AUTOSAR XML (schema 3.1.2)
package /Components/SWC_CoGBx
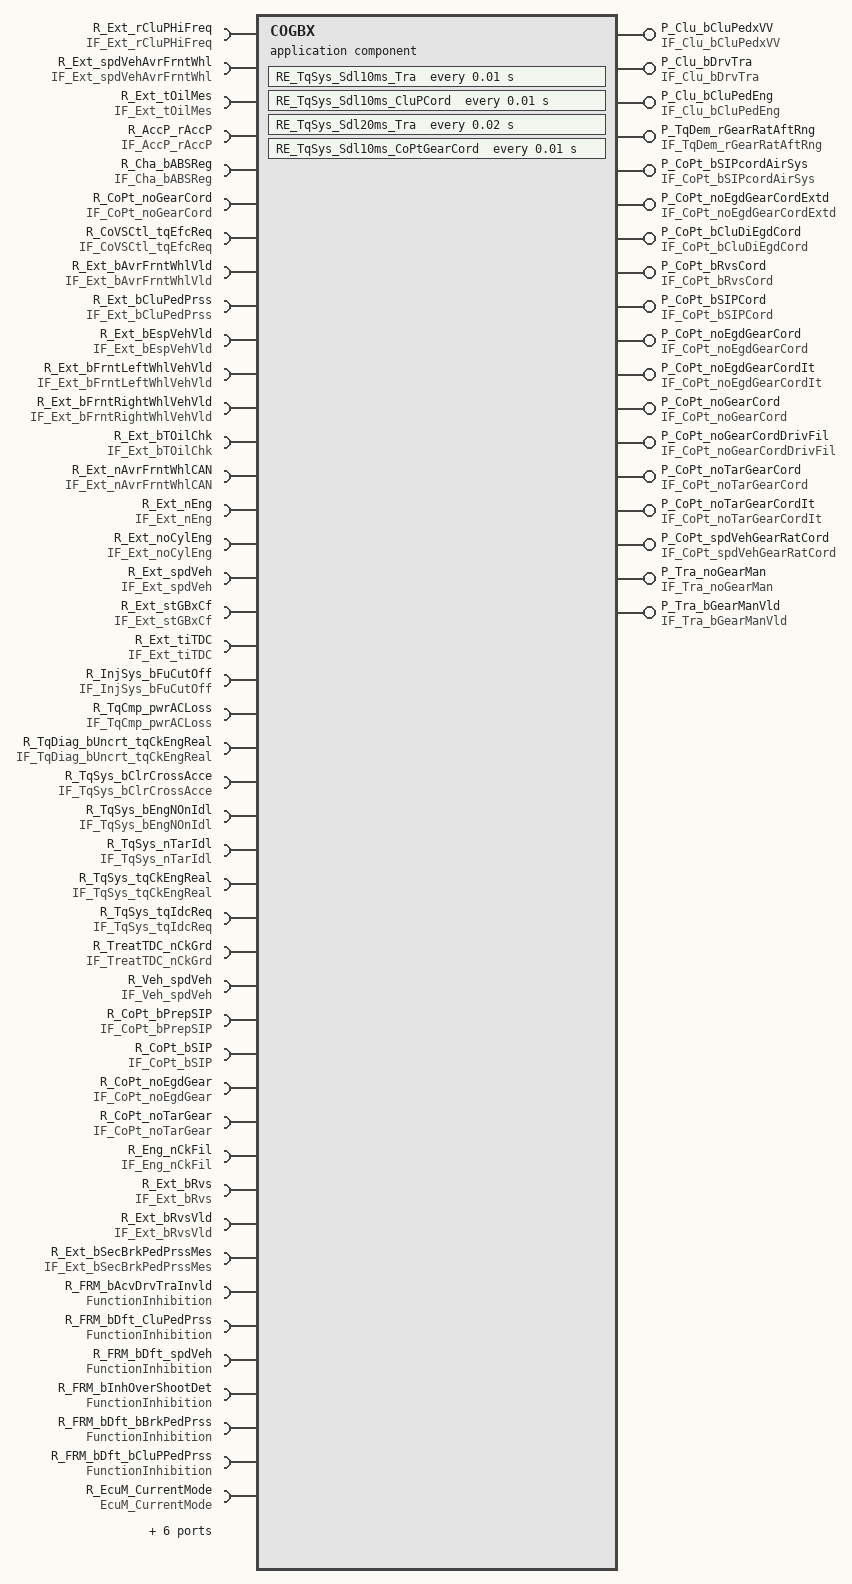
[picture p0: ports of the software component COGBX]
  application software component type COGBX
    43 x require port:
      R_Ext_rCluPHiFreq: unqueued-receiver-com-spec{data-element=Ext_rCluPHiFreq, init-value=ConstantValue, resync-time=0}, required-interface=IF_Ext_rCluPHiFreq
      R_Ext_spdVehAvrFrntWhl: unqueued-receiver-com-spec{data-element=Ext_spdVehAvrFrntWhl, init-value=Ext_spdVehAvrFrntWhl_in, resync-time=0}, required-interface=IF_Ext_spdVehAvrFrntWhl
      R_Ext_tOilMes: unqueued-receiver-com-spec{data-element=Ext_tOilMes, init-value=Ext_tOilMes_in, resync-time=0}, required-interface=IF_Ext_tOilMes
      R_AccP_rAccP: unqueued-receiver-com-spec{data-element=AccP_rAccP, init-value=ConstantValue1, resync-time=0}, required-interface=IF_AccP_rAccP
      R_Cha_bABSReg: unqueued-receiver-com-spec{data-element=Cha_bABSReg, init-value=Cha_bABSReg_in, resync-time=0}, required-interface=IF_Cha_bABSReg
      R_CoPt_noGearCord: unqueued-receiver-com-spec{data-element=CoPt_noGearCord, init-value=ConstantValue3, resync-time=0}, required-interface=IF_CoPt_noGearCord
      R_CoVSCtl_tqEfcReq: unqueued-receiver-com-spec{data-element=CoVSCtl_tqEfcReq, init-value=CoVSCtl_tqEfcReq_in, resync-time=0}, required-interface=IF_CoVSCtl_tqEfcReq
      R_Ext_bAvrFrntWhlVld: unqueued-receiver-com-spec{data-element=Ext_bAvrFrntWhlVld, init-value=Ext_bAvrFrntWhlVld_in, resync-time=0}, required-interface=IF_Ext_bAvrFrntWhlVld
      R_Ext_bCluPedPrss: unqueued-receiver-com-spec{data-element=Ext_bCluPedPrss, init-value=ConstantValue5, resync-time=0}, required-interface=IF_Ext_bCluPedPrss
      R_Ext_bEspVehVld: unqueued-receiver-com-spec{data-element=Ext_bEspVehVld, init-value=Ext_bEspVehVld_in, resync-time=0}, required-interface=IF_Ext_bEspVehVld
      R_Ext_bFrntLeftWhlVehVld: unqueued-receiver-com-spec{data-element=Ext_bFrntLeftWhlVehVld, init-value=Ext_bFrntLeftWhlVehVld_in, resync-time=0}, required-interface=IF_Ext_bFrntLeftWhlVehVld
      R_Ext_bFrntRightWhlVehVld: unqueued-receiver-com-spec{data-element=Ext_bFrntRightWhlVehVld, init-value=Ext_bFrntRightWhlVehVld_in, resync-time=0}, required-interface=IF_Ext_bFrntRightWhlVehVld
      R_Ext_bTOilChk: unqueued-receiver-com-spec{data-element=Ext_bTOilChk, init-value=Ext_bTOilChk_in, resync-time=0}, required-interface=IF_Ext_bTOilChk
      R_Ext_nAvrFrntWhlCAN: unqueued-receiver-com-spec{data-element=Ext_nAvrFrntWhlCAN, init-value=Ext_nAvrFrntWhlCAN_in, resync-time=0}, required-interface=IF_Ext_nAvrFrntWhlCAN
      R_Ext_nEng: unqueued-receiver-com-spec{data-element=Ext_nEng, init-value=ConstantValue7, resync-time=0}, required-interface=IF_Ext_nEng
      R_Ext_noCylEng: unqueued-receiver-com-spec{data-element=Ext_noCylEng, init-value=Ext_noCylEng_in, resync-time=0}, required-interface=IF_Ext_noCylEng
      R_Ext_spdVeh: unqueued-receiver-com-spec{data-element=Ext_spdVeh, init-value=ConstantValue9, resync-time=0}, required-interface=IF_Ext_spdVeh
      R_Ext_stGBxCf: unqueued-receiver-com-spec{data-element=Ext_stGBxCf, init-value=ConstantValue11, resync-time=0}, required-interface=IF_Ext_stGBxCf
      R_Ext_tiTDC: unqueued-receiver-com-spec{data-element=Ext_tiTDC, init-value=ConstantValue13, resync-time=0}, required-interface=IF_Ext_tiTDC
      R_InjSys_bFuCutOff: unqueued-receiver-com-spec{data-element=InjSys_bFuCutOff, init-value=InjSys_bFuCutOff_in, resync-time=0}, required-interface=IF_InjSys_bFuCutOff
      R_TqCmp_pwrACLoss: unqueued-receiver-com-spec{data-element=TqCmp_pwrACLoss, init-value=TqCmp_pwrACLoss_in, resync-time=0}, required-interface=IF_TqCmp_pwrACLoss
      R_TqDiag_bUncrt_tqCkEngReal: unqueued-receiver-com-spec{data-element=TqDiag_bUncrt_tqCkEngReal, init-value=TqDiag_bUncrt_tqCkEngReal_in, resync-time=0}, required-interface=IF_TqDiag_bUncrt_tqCkEngReal
      R_TqSys_bClrCrossAcce: unqueued-receiver-com-spec{data-element=TqSys_bClrCrossAcce, init-value=TqSys_bClrCrossAcce_in, resync-time=0}, required-interface=IF_TqSys_bClrCrossAcce
      R_TqSys_bEngNOnIdl: unqueued-receiver-com-spec{data-element=TqSys_bEngNOnIdl, init-value=ConstantValue15, resync-time=0}, required-interface=IF_TqSys_bEngNOnIdl
      R_TqSys_nTarIdl: unqueued-receiver-com-spec{data-element=TqSys_nTarIdl, init-value=ConstantValue17, resync-time=0}, required-interface=IF_TqSys_nTarIdl
      R_TqSys_tqCkEngReal: unqueued-receiver-com-spec{data-element=TqSys_tqCkEngReal, init-value=TqSys_tqCkEngReal_in, resync-time=0}, required-interface=IF_TqSys_tqCkEngReal
      R_TqSys_tqIdcReq: unqueued-receiver-com-spec{data-element=TqSys_tqIdcReq, init-value=ConstantValue19, resync-time=0}, required-interface=IF_TqSys_tqIdcReq
      R_TreatTDC_nCkGrd: unqueued-receiver-com-spec{data-element=TreatTDC_nCkGrd, init-value=ConstantValue21, resync-time=0}, required-interface=IF_TreatTDC_nCkGrd
      R_Veh_spdVeh: unqueued-receiver-com-spec{data-element=Veh_spdVeh, init-value=ConstantValue23, resync-time=0}, required-interface=IF_Veh_spdVeh
      R_CoPt_bPrepSIP: unqueued-receiver-com-spec{data-element=CoPt_bPrepSIP, init-value=CoPt_bPrepSIP_in, resync-time=0}, required-interface=IF_CoPt_bPrepSIP
      R_CoPt_bSIP: unqueued-receiver-com-spec{data-element=CoPt_bSIP, init-value=ConstantValue25, resync-time=0}, required-interface=IF_CoPt_bSIP
      R_CoPt_noEgdGear: unqueued-receiver-com-spec{data-element=CoPt_noEgdGear, init-value=CoPt_noEgdGear_in, resync-time=0}, required-interface=IF_CoPt_noEgdGear
      R_CoPt_noTarGear: unqueued-receiver-com-spec{data-element=CoPt_noTarGear, init-value=CoPt_noTarGear_in, resync-time=0}, required-interface=IF_CoPt_noTarGear
      R_Eng_nCkFil: unqueued-receiver-com-spec{data-element=Eng_nCkFil, init-value=ConstantValue27, resync-time=0}, required-interface=IF_Eng_nCkFil
      R_Ext_bRvs: unqueued-receiver-com-spec{data-element=Ext_bRvs, init-value=Ext_bRvs_in, resync-time=0}, required-interface=IF_Ext_bRvs
      R_Ext_bRvsVld: unqueued-receiver-com-spec{data-element=Ext_bRvsVld, init-value=Ext_bRvsVld_in, resync-time=0}, required-interface=IF_Ext_bRvsVld
      R_Ext_bSecBrkPedPrssMes: unqueued-receiver-com-spec{data-element=Ext_bSecBrkPedPrssMes, init-value=ConstantValue29, resync-time=0}, required-interface=IF_Ext_bSecBrkPedPrssMes
      R_FRM_bAcvDrvTraInvld: required-interface=FunctionInhibition
      R_FRM_bDft_CluPedPrss: required-interface=FunctionInhibition
      R_FRM_bDft_spdVeh: required-interface=FunctionInhibition
      R_FRM_bInhOverShootDet: required-interface=FunctionInhibition
      R_FRM_bDft_bBrkPedPrss: required-interface=FunctionInhibition
      R_FRM_bDft_bCluPPedPrss: required-interface=FunctionInhibition
    16 x provide port:
      P_Clu_bCluPedxVV: unqueued-sender-com-spec{data-element=Clu_bCluPedxVV, can-invalidate=false, init-value=Clu_bCluPedxVV_out}, provided-interface=IF_Clu_bCluPedxVV
      P_Clu_bDrvTra: unqueued-sender-com-spec{data-element=Clu_bDrvTra, can-invalidate=false, init-value=Clu_bDrvTra_out}, provided-interface=IF_Clu_bDrvTra
      P_Clu_bCluPedEng: unqueued-sender-com-spec{data-element=Clu_bCluPedEng, can-invalidate=false, init-value=Clu_bCluPedEng_out}, provided-interface=IF_Clu_bCluPedEng
      P_TqDem_rGearRatAftRng: unqueued-sender-com-spec{data-element=TqDem_rGearRatAftRng, can-invalidate=false, init-value=TqDem_rGearRatAftRng_out}, provided-interface=IF_TqDem_rGearRatAftRng
      P_CoPt_bSIPcordAirSys: unqueued-sender-com-spec{data-element=CoPt_bSIPcordAirSys, can-invalidate=false, init-value=CoPt_bSIPcordAirSys_out}, provided-interface=IF_CoPt_bSIPcordAirSys
      P_CoPt_noEgdGearCordExtd: unqueued-sender-com-spec{data-element=CoPt_noEgdGearCordExtd, can-invalidate=false, init-value=CoPt_noEgdGearCordExtd_out}, provided-interface=IF_CoPt_noEgdGearCordExtd
      P_CoPt_bCluDiEgdCord: unqueued-sender-com-spec{data-element=CoPt_bCluDiEgdCord, can-invalidate=false, init-value=ConstantValue31}, provided-interface=IF_CoPt_bCluDiEgdCord
      P_CoPt_bRvsCord: unqueued-sender-com-spec{data-element=CoPt_bRvsCord, can-invalidate=false, init-value=CoPt_bRvsCord_out}, provided-interface=IF_CoPt_bRvsCord
      P_CoPt_bSIPCord: unqueued-sender-com-spec{data-element=CoPt_bSIPCord, can-invalidate=false, init-value=ConstantValue33}, provided-interface=IF_CoPt_bSIPCord
      P_CoPt_noEgdGearCord: unqueued-sender-com-spec{data-element=CoPt_noEgdGearCord, can-invalidate=false, init-value=ConstantValue35}, provided-interface=IF_CoPt_noEgdGearCord
      P_CoPt_noEgdGearCordIt: unqueued-sender-com-spec{data-element=CoPt_noEgdGearCordIt, can-invalidate=false, init-value=ConstantValue37}, provided-interface=IF_CoPt_noEgdGearCordIt
      P_CoPt_noGearCord: unqueued-sender-com-spec{data-element=CoPt_noGearCord, can-invalidate=false, init-value=ConstantValue39}, provided-interface=IF_CoPt_noGearCord
      P_CoPt_noGearCordDrivFil: unqueued-sender-com-spec{data-element=CoPt_noGearCordDrivFil, can-invalidate=false, init-value=ConstantValue41}, provided-interface=IF_CoPt_noGearCordDrivFil
      P_CoPt_noTarGearCord: unqueued-sender-com-spec{data-element=CoPt_noTarGearCord, can-invalidate=false, init-value=CoPt_noTarGearCord_out}, provided-interface=IF_CoPt_noTarGearCord
      P_CoPt_noTarGearCordIt: unqueued-sender-com-spec{data-element=CoPt_noTarGearCordIt, can-invalidate=false, init-value=CoPt_noTarGearCordIt_out}, provided-interface=IF_CoPt_noTarGearCordIt
      P_CoPt_spdVehGearRatCord: unqueued-sender-com-spec{data-element=CoPt_spdVehGearRatCord, can-invalidate=false, init-value=CoPt_spdVehGearRatCord_out}, provided-interface=IF_CoPt_spdVehGearRatCord
    5 x require port:
      R_EcuM_CurrentMode: required-interface=EcuM_CurrentMode
      R_TqSys_EveSyncFrame30D_Tra: unqueued-receiver-com-spec{data-element=TqSys_EveSyncFrame30D_Tra, init-value=TqSys_EveSyncFrame30D_Tra_Cst, resync-time=0}, required-interface=IF_TqSys_EveSyncFrame30D_Tra
      R_TqSys_EveSyncFrame38D_Tra: unqueued-receiver-com-spec{data-element=TqSys_EveSyncFrame38D_Tra, init-value=TqSys_EveSyncFrame30D_Tra_cst, resync-time=0}, required-interface=IF_TqSys_EveSyncFrame38D_Tra
      R_TqSys_EveSync_Tra: unqueued-receiver-com-spec{data-element=TqSys_EveSync_Tra, init-value=TqSys_EveSync_Tra_Cst, resync-time=0}, required-interface=IF_TqSys_EveSync_Tra
      R_Tra_noGearMan: unqueued-receiver-com-spec{data-element=Tra_noGearMan, init-value=Tra_noGearMan, resync-time=0}, required-interface=IF_Tra_noGearMan
    provide port P_Tra_noGearMan: unqueued-sender-com-spec{data-element=Tra_noGearMan, can-invalidate=false, init-value=Tra_noGearMan}, provided-interface=IF_Tra_noGearMan
    require port R_UCE_stWkuMainRelSt: required-interface=IF_UCE_stWkuMainRelSt
    provide port P_Tra_bGearManVld: unqueued-sender-com-spec{data-element=Tra_bGearManVld, can-invalidate=false, init-value=Tra_bGearManVld_irv}, provided-interface=IF_Tra_bGearManVld
    require port R_Tra_bGearManVld: unqueued-receiver-com-spec{data-element=Tra_bGearManVld, init-value=Tra_bGearManVld_irv, resync-time=0}, required-interface=IF_Tra_bGearManVld
  66 x constant specification:
    Cha_bABSReg_in
      value:
        boolean literal Cha_bABSReg_in: type=DT_Cha_bABSReg, value=false
    Clu_bCluPedEng_out
      value:
        boolean literal Clu_bCluPedEng_out: type=DT_Clu_bCluPedEng, value=false
    Clu_bCluPedxVV_out
      value:
        boolean literal Clu_bCluPedxVV_out: type=DT_Clu_bCluPedxVV, value=false
    Clu_bDrvTra_out
      value:
        boolean literal Clu_bDrvTra_out: type=DT_Clu_bDrvTra, value=false
    ConstantValue
      value:
        integer literal ConstantValue: type=DT_Ext_rCluPHiFreq, value=0
    ConstantValue1
      value:
        integer literal ConstantValue1: type=DT_AccP_rAccP, value=0
    ConstantValue11
      value:
        integer literal ConstantValue11: type=DT_Ext_stGBxCf, value=0
    ConstantValue13
      value:
        integer literal ConstantValue13: type=DT_Ext_tiTDC, value=100
    ConstantValue15
      value:
        boolean literal ConstantValue15: type=DT_TqSys_bEngNOnIdl, value=true
    ConstantValue17
      value:
        integer literal ConstantValue17: type=DT_TqSys_nTarIdl, value=0
    ConstantValue19
      value:
        integer literal ConstantValue19: type=DT_TqSys_tqIdcReq, value=0
    ConstantValue21
      value:
        integer literal ConstantValue21: type=DT_TreatTDC_nCkGrd, value=0
    ConstantValue23
      value:
        integer literal ConstantValue23: type=DT_Veh_spdVeh, value=0
    ConstantValue25
      value:
        boolean literal ConstantValue25: type=DT_CoPt_bSIP, value=false
    ConstantValue27
      value:
        integer literal ConstantValue27: type=DT_Eng_nCkFil, value=0
    ConstantValue29
      value:
        boolean literal ConstantValue29: type=DT_Ext_bSecBrkPedPrssMes, value=false
    ConstantValue3
      value:
        integer literal ConstantValue3: type=DT_CoPt_noGearCord, value=0
    ConstantValue31
      value:
        boolean literal ConstantValue31: type=DT_CoPt_bCluDiEgdCord, value=false
    ConstantValue33
      value:
        boolean literal ConstantValue33: type=DT_CoPt_bSIPCord, value=false
    ConstantValue35
      value:
        integer literal ConstantValue35: type=DT_CoPt_noEgdGearCord, value=0
    ConstantValue37
      value:
        integer literal ConstantValue37: type=DT_CoPt_noEgdGearCordIt, value=0
    ConstantValue39
      value:
        integer literal ConstantValue39: type=DT_CoPt_noGearCord, value=0
    ConstantValue41
      value:
        integer literal ConstantValue41: type=DT_CoPt_noGearCordDrivFil, value=0
    ConstantValue5
      value:
        boolean literal ConstantValue5: type=DT_Ext_bCluPedPrss, value=false
    ConstantValue7
      value:
        integer literal ConstantValue7: type=DT_Ext_nEng, value=0
    ConstantValue9
      value:
        integer literal ConstantValue9: type=DT_Ext_spdVeh, value=0
    CoPt_bPrepSIP_in
      value:
        boolean literal CoPt_bPrepSIP_in: type=DT_CoPt_bPrepSIP, value=false
    CoPt_bRvsCord_out
      value:
        boolean literal CoPt_bRvsCord_out: type=DT_CoPt_bRvsCord, value=false
    CoPt_bSIPcordAirSys_out
      value:
        boolean literal CoPt_bSIPcordAirSys_out: type=DT_CoPt_bSIPcordAirSys, value=false
    CoPt_noEgdGear_in
      value:
        integer literal CoPt_noEgdGear_in: type=DT_CoPt_noEgdGear, value=0
    CoPt_noEgdGearCordExtd_out
      value:
        integer literal CoPt_noEgdGearCordExtd_out: type=DT_CoPt_noEgdGearCordExtd, value=0
    CoPt_noTarGear_in
      value:
        integer literal CoPt_noTarGear_in: type=DT_CoPt_noTarGear, value=0
    CoPt_noTarGearCord_out
      value:
        integer literal CoPt_noTarGearCord_out: type=DT_CoPt_noTarGearCord, value=0
    CoPt_noTarGearCordIt_out
      value:
        integer literal CoPt_noTarGearCordIt_out: type=DT_CoPt_noTarGearCordIt, value=0
    CoPt_spdVehGearRatCord_out
      value:
        integer literal CoPt_spdVehGearRatCord_out: type=DT_CoPt_spdVehGearRatCord, value=0
    CoVSCtl_tqEfcReq_in
      value:
        integer literal CoVSCtl_tqEfcReq_in: type=DT_CoVSCtl_tqEfcReq, value=0
    Ext_bAvrFrntWhlVld_in
      value:
        boolean literal Ext_bAvrFrntWhlVld_in: type=DT_Ext_bAvrFrntWhlVld, value=true
    Ext_bEspVehVld_in
      value:
        boolean literal Ext_bEspVehVld_in: type=DT_Ext_bEspVehVld, value=true
    Ext_bFrntLeftWhlVehVld_in
      value:
        boolean literal Ext_bFrntLeftWhlVehVld_in: type=DT_Ext_bFrntLeftWhlVehVld, value=true
    Ext_bFrntRightWhlVehVld_in
      value:
        boolean literal Ext_bFrntRightWhlVehVld_in: type=DT_Ext_bFrntRightWhlVehVld, value=true
    Ext_bRvs_in
      value:
        boolean literal Ext_bRvs_in: type=DT_Ext_bRvs, value=false
    Ext_bRvsVld_in
      value:
        boolean literal Ext_bRvsVld_in: type=DT_Ext_bRvsVld, value=false
    Ext_bTOilChk_in
      value:
        boolean literal Ext_bTOilChk_in: type=DT_Ext_bTOilChk, value=false
    Ext_nAvrFrntWhlCAN_in
      value:
        integer literal Ext_nAvrFrntWhlCAN_in: type=DT_Ext_nAvrFrntWhlCAN, value=0
    Ext_noCylEng_in
      value:
        integer literal Ext_noCylEng_in: type=DT_Ext_noCylEng, value=1
    Ext_spdVehAvrFrntWhl_in
      value:
        integer literal Ext_spdVehAvrFrntWhl_in: type=DT_Ext_spdVehAvrFrntWhl, value=0
    Ext_tOilMes_in
      value:
        integer literal Ext_tOilMes_in: type=DT_Ext_tOilMes, value=0
    InjSys_bFuCutOff_in
      value:
        boolean literal InjSys_bFuCutOff_in: type=DT_InjSys_bFuCutOff, value=false
    TqCmp_pwrACLoss_in
      value:
        integer literal TqCmp_pwrACLoss_in: type=DT_TqCmp_pwrACLoss, value=0
    TqDem_bGearRatCdnVld1_irv_Cst
      value:
        boolean literal TqDem_bGearRatCdnVld1_irv_Cst: type=DT_TqDem_bGearRatCdnVld1_irv, value=false
    TqDem_n6CylEngMvFil_irv
      value:
        integer literal TqDem_n6CylEngMvFil_irv: type=DT_TqDem_n6CylEngMvFil_irv, value=0
    TqDem_rGearRatAftRng_out
      value:
        integer literal TqDem_rGearRatAftRng_out: type=DT_TqDem_rGearRatAftRng, value=0
    TqDem_rPedPrssGrd_irv_Cst
      value:
        integer literal TqDem_rPedPrssGrd_irv_Cst: type=DT_TqDem_rPedPrssGrd_irv, value=0
    TqDem_spdVehFil1_irv
      value:
        integer literal TqDem_spdVehFil1_irv: type=DT_TqDem_spdVehFil1_irv, value=0
    TqDem_spdVehFil1_irv_Cst
      value:
        integer literal TqDem_spdVehFil1_irv_Cst: type=DT_TqDem_spdWhlFil1_irv, value=0
    TqDem_stGearratOverNRise_irv_Cst
      value:
        boolean literal TqDem_stGearratOverNRise_irv_Cst: type=DT_TqDem_stGearratOverNRise_irv, value=false
    TqDem_tqTqRealSyncFuseMv_irv_Cst
      value:
        integer literal TqDem_tqTqRealSyncFuseMv_irv_Cst: type=DT_TqDem_tqTqRealSyncFuseMv_irv, value=0
    TqDiag_bUncrt_tqCkEngReal_in
      value:
        boolean literal TqDiag_bUncrt_tqCkEngReal_in: type=DT_TqDiag_bUncrt_tqCkEngReal, value=false
    TqSys_bClrCrossAcce_in
      value:
        boolean literal TqSys_bClrCrossAcce_in: type=DT_TqSys_bClrCrossAcce, value=false
    TqSys_EveSync_Tra_Cst
      value:
        boolean literal TqSys_EveSync_Tra_Cst: type=DT_TqSys_EveSync_Tra, value=false
    TqSys_EveSyncFrame30D_Tra_cst
      value:
        boolean literal TqSys_EveSyncFrame30D_Tra_cst: type=DT_TqSys_EveSyncFrame38D_Tra, value=false
    TqSys_EveSyncFrame30D_Tra_Cst
      value:
        boolean literal TqSys_EveSyncFrame30D_Tra_Cst: type=DT_TqSys_EveSyncFrame30D_Tra, value=false
    TqSys_tqCkEngReal_in
      value:
        integer literal TqSys_tqCkEngReal_in: type=DT_TqSys_tqCkEngReal, value=0
    Tra_bGearManVld_irv
      value:
        boolean literal Tra_bGearManVld_irv: type=DT_Tra_bGearManVld, value=false
    Tra_noGearMan
      value:
        integer literal Tra_noGearMan: type=DT_Tra_noGearMan, value=0
    Tra_spdVehGearRatCord_irv_Cst
      value:
        integer literal Tra_spdVehGearRatCord_irv_Cst: type=DT_Tra_spdVehGearRatCord_irv, value=0
  internal behavior IB_CoGBx: component=COGBX
    timing event EV_TqSys_Sdl10ms_Tra: start-on-event=RE_TqSys_Sdl10ms_Tra, period=0.01
    timing event EV_TqSys_Sdl10ms_CluPCord: start-on-event=RE_TqSys_Sdl10ms_CluPCord, period=0.01
    data received event EV_TqSys_EveSyncFrame38D_Tra: start-on-event=RE_TqSys_EveSyncFrame38D_Tra, data=R_TqSys_EveSyncFrame38D_Tra.TqSys_EveSyncFrame38D_Tra
    mode switch event EV_CoGBx_001_MSE: start-on-event=RE_CoGBx_001_MSE, activation=ENTRY, mode=R_EcuM_CurrentMode.currentMode.RUN
    data received event EV_TqSys_EveSync_Tra: start-on-event=RE_TqSys_EveSync_Tra, data=R_TqSys_EveSync_Tra.TqSys_EveSync_Tra
    timing event EV_TqSys_Sdl20ms_Tra: start-on-event=RE_TqSys_Sdl20ms_Tra, period=0.02
    timing event EV_TqSys_Sdl10ms_CoPtGearCord: start-on-event=RE_TqSys_Sdl10ms_CoPtGearCord, period=0.01
    data received event EV_TqSys_EveSyncFrame30D_Tra: start-on-event=RE_TqSys_EveSyncFrame30D_Tra, data=R_TqSys_EveSyncFrame30D_Tra.TqSys_EveSyncFrame30D_Tra
    8 x inter runnable variable, all with sw-calibration-access=READ-WRITE, communication-approach=EXPLICIT:
      TqDem_spdVehFil1_irv: type=DT_TqDem_spdVehFil1_irv, init-value=TqDem_spdVehFil1_irv
      TqDem_stGearratOverNRise_irv: type=DT_TqDem_stGearratOverNRise_irv, init-value=TqDem_stGearratOverNRise_irv_Cst
      TqDem_n6CylEngMvFil_irv: type=DT_TqDem_n6CylEngMvFil_irv, init-value=TqDem_n6CylEngMvFil_irv
      TqDem_spdWhlFil1_irv: type=DT_TqDem_spdWhlFil1_irv, init-value=TqDem_spdVehFil1_irv_Cst
      TqDem_tqTqRealSyncFuseMv_irv: type=DT_TqDem_tqTqRealSyncFuseMv_irv, init-value=TqDem_tqTqRealSyncFuseMv_irv_Cst
      TqDem_bGearRatCdnVld1_irv: type=DT_TqDem_bGearRatCdnVld1_irv, init-value=TqDem_bGearRatCdnVld1_irv_Cst
      Tra_spdVehGearRatCord_irv: type=DT_Tra_spdVehGearRatCord_irv, init-value=Tra_spdVehGearRatCord_irv_Cst
      TqDem_rPedPrssGrd_irv: type=DT_TqDem_rPedPrssGrd_irv, init-value=TqDem_rPedPrssGrd_irv_Cst
    8 x runnable:
      RE_TqSys_EveSyncFrame38D_Tra: written-variable=TqDem_spdVehFil1_irv
        data receive point dr_Ext_spdVeh: data-element=R_Ext_spdVeh.Ext_spdVeh
      RE_CoGBx_001_MSE: written-variable=[TqDem_stGearratOverNRise_irv, TqDem_bGearRatCdnVld1_irv, TqDem_rPedPrssGrd_irv, TqDem_n6CylEngMvFil_irv, TqDem_spdVehFil1_irv, TqDem_spdWhlFil1_irv, Tra_spdVehGearRatCord_irv, TqDem_tqTqRealSyncFuseMv_irv]
        18 x data send point:
          DS_CoPt_bRvsCord: data-element=P_CoPt_bRvsCord.CoPt_bRvsCord
          DS_CoPt_spdVehGearRatCord: data-element=P_CoPt_spdVehGearRatCord.CoPt_spdVehGearRatCord
          ds_CoPt_bSIPCord: data-element=P_CoPt_bSIPCord.CoPt_bSIPCord
          DS_Tra_noGearMan: data-element=P_Tra_noGearMan.Tra_noGearMan
          ds_CoPt_noEgdGearCord: data-element=P_CoPt_noEgdGearCord.CoPt_noEgdGearCord
          ds_CoPt_noGearCordDrivFil: data-element=P_CoPt_noGearCordDrivFil.CoPt_noGearCordDrivFil
          DS_Tra_bGearManVld: data-element=P_Tra_bGearManVld.Tra_bGearManVld
          DS_Clu_bCluPedEng: data-element=P_Clu_bCluPedEng.Clu_bCluPedEng
          DS_Clu_bCluPedxVV: data-element=P_Clu_bCluPedxVV.Clu_bCluPedxVV
          DS_CoPt_noTarGearCord: data-element=P_CoPt_noTarGearCord.CoPt_noTarGearCord
          ds_CoPt_bCluDiEgdCord: data-element=P_CoPt_bCluDiEgdCord.CoPt_bCluDiEgdCord
          DS_CoPt_bSIPcordAirSys: data-element=P_CoPt_bSIPcordAirSys.CoPt_bSIPcordAirSys
          DS_Clu_bDrvTra: data-element=P_Clu_bDrvTra.Clu_bDrvTra
          ds_CoPt_noGearCord: data-element=P_CoPt_noGearCord.CoPt_noGearCord
          DS_TqDem_rGearRatAftRng: data-element=P_TqDem_rGearRatAftRng.TqDem_rGearRatAftRng
          DS_CoPt_noTarGearCordIt: data-element=P_CoPt_noTarGearCordIt.CoPt_noTarGearCordIt
          ds_CoPt_noEgdGearCordIt: data-element=P_CoPt_noEgdGearCordIt.CoPt_noEgdGearCordIt
          DS_CoPt_noEgdGearCordExtd: data-element=P_CoPt_noEgdGearCordExtd.CoPt_noEgdGearCordExtd
      RE_TqSys_Sdl10ms_CoPtGearCord: read-variable=Tra_spdVehGearRatCord_irv
        14 x data receive point:
          DR_CoPt_noTarGear: data-element=R_CoPt_noTarGear.CoPt_noTarGear
          dr_Ext_stGBxCf: data-element=R_Ext_stGBxCf.Ext_stGBxCf
          DR_Ext_bRvsVld: data-element=R_Ext_bRvsVld.Ext_bRvsVld
          dr_Ext_bSecBrkPedPrssMes: data-element=R_Ext_bSecBrkPedPrssMes.Ext_bSecBrkPedPrssMes
          DR_Tra_noGearMan: data-element=R_Tra_noGearMan.Tra_noGearMan
          dr_Eng_nCkFil: data-element=R_Eng_nCkFil.Eng_nCkFil
          DR_CoPt_noEgdGear: data-element=R_CoPt_noEgdGear.CoPt_noEgdGear
          dr_Ext_bCluPedPrss: data-element=R_Ext_bCluPedPrss.Ext_bCluPedPrss
          dr_Veh_spdVeh: data-element=R_Veh_spdVeh.Veh_spdVeh
          DR_CoPt_bPrepSIP: data-element=R_CoPt_bPrepSIP.CoPt_bPrepSIP
          DR_Ext_bRvs: data-element=R_Ext_bRvs.Ext_bRvs
          DR_Tra_bGearManVld: data-element=R_Tra_bGearManVld.Tra_bGearManVld
          dr_CoPt_bSIP: data-element=R_CoPt_bSIP.CoPt_bSIP
          dr_AccP_rAccP: data-element=R_AccP_rAccP.AccP_rAccP
        12 x data send point:
          ds_CoPt_bSIPCord: data-element=P_CoPt_bSIPCord.CoPt_bSIPCord
          ds_CoPt_noEgdGearCord: data-element=P_CoPt_noEgdGearCord.CoPt_noEgdGearCord
          DS_CoPt_bSIPcordAirSys: data-element=P_CoPt_bSIPcordAirSys.CoPt_bSIPcordAirSys
          DS_CoPt_bRvsCord: data-element=P_CoPt_bRvsCord.CoPt_bRvsCord
          ds_CoPt_bCluDiEgdCord: data-element=P_CoPt_bCluDiEgdCord.CoPt_bCluDiEgdCord
          DS_CoPt_noEgdGearCordExtd: data-element=P_CoPt_noEgdGearCordExtd.CoPt_noEgdGearCordExtd
          DS_CoPt_noTarGearCord: data-element=P_CoPt_noTarGearCord.CoPt_noTarGearCord
          ds_CoPt_noGearCord: data-element=P_CoPt_noGearCord.CoPt_noGearCord
          ds_CoPt_noGearCordDrivFil: data-element=P_CoPt_noGearCordDrivFil.CoPt_noGearCordDrivFil
          DS_CoPt_noTarGearCordIt: data-element=P_CoPt_noTarGearCordIt.CoPt_noTarGearCordIt
          DS_CoPt_spdVehGearRatCord: data-element=P_CoPt_spdVehGearRatCord.CoPt_spdVehGearRatCord
          ds_CoPt_noEgdGearCordIt: data-element=P_CoPt_noEgdGearCordIt.CoPt_noEgdGearCordIt
        sync call SC_FRM_bDft_bBrkPedPrss: operation=R_FRM_bDft_bBrkPedPrss.GetFunctionPermission
        sync call SC_FRM_bDft_bCluPPedPrss: operation=R_FRM_bDft_bCluPPedPrss.GetFunctionPermission
        sync call SC_FRM_bDft_spdVeh: operation=R_FRM_bDft_spdVeh.GetFunctionPermission
      RE_TqSys_Sdl10ms_CluPCord
        data receive point dr_Ext_rCluPHiFreq: data-element=R_Ext_rCluPHiFreq.Ext_rCluPHiFreq
        data send point DS_Clu_bCluPedEng: data-element=P_Clu_bCluPedEng.Clu_bCluPedEng
        data send point DS_Clu_bCluPedxVV: data-element=P_Clu_bCluPedxVV.Clu_bCluPedxVV
        data send point DS_Clu_bDrvTra: data-element=P_Clu_bDrvTra.Clu_bDrvTra
        sync call SC_FRM_bAcvDrvTraInvld: operation=R_FRM_bAcvDrvTraInvld.GetFunctionPermission
      RE_TqSys_EveSyncFrame30D_Tra: written-variable=TqDem_spdWhlFil1_irv
        data receive point DR_Ext_spdVehAvrFrntWhl: data-element=R_Ext_spdVehAvrFrntWhl.Ext_spdVehAvrFrntWhl
      RE_TqSys_EveSync_Tra: read-variable=[TqDem_rPedPrssGrd_irv, TqDem_bGearRatCdnVld1_irv], written-variable=[TqDem_tqTqRealSyncFuseMv_irv, TqDem_n6CylEngMvFil_irv, TqDem_stGearratOverNRise_irv]
        14 x data receive point:
          DR_Ext_noCylEng: data-element=R_Ext_noCylEng.Ext_noCylEng
          dr_Ext_nEng: data-element=R_Ext_nEng.Ext_nEng
          dr_TreatTDC_nCkGrd: data-element=R_TreatTDC_nCkGrd.TreatTDC_nCkGrd
          dr_TqSys_bEngNOnIdl: data-element=R_TqSys_bEngNOnIdl.TqSys_bEngNOnIdl
          dr_Ext_bCluPedPrss: data-element=R_Ext_bCluPedPrss.Ext_bCluPedPrss
          DR_InjSys_bFuCutOff: data-element=R_InjSys_bFuCutOff.InjSys_bFuCutOff
          dr_Ext_tiTDC: data-element=R_Ext_tiTDC.Ext_tiTDC
          DR_Ext_tOilMes: data-element=R_Ext_tOilMes.Ext_tOilMes
          DR_Tra_noGearMan: data-element=R_Tra_noGearMan.Tra_noGearMan
          DR_TqCmp_pwrACLoss: data-element=R_TqCmp_pwrACLoss.TqCmp_pwrACLoss
          dr_TqSys_tqIdcReq: data-element=R_TqSys_tqIdcReq.TqSys_tqIdcReq
          DR_Ext_bTOilChk: data-element=R_Ext_bTOilChk.Ext_bTOilChk
          DR_TqSys_tqCkEngReal: data-element=R_TqSys_tqCkEngReal.TqSys_tqCkEngReal
          DR_TqDiag_bUncrt_tqCkEngReal: data-element=R_TqDiag_bUncrt_tqCkEngReal.TqDiag_bUncrt_tqCkEngReal
        sync call SC_FRM_bInhOverShootDet: operation=R_FRM_bInhOverShootDet.GetFunctionPermission
      RE_TqSys_Sdl20ms_Tra
        4 x data receive point:
          DR_Ext_bAvrFrntWhlVld: data-element=R_Ext_bAvrFrntWhlVld.Ext_bAvrFrntWhlVld
          DR_Ext_bFrntLeftWhlVehVld: data-element=R_Ext_bFrntLeftWhlVehVld.Ext_bFrntLeftWhlVehVld
          DR_Ext_bFrntRightWhlVehVld: data-element=R_Ext_bFrntRightWhlVehVld.Ext_bFrntRightWhlVehVld
          DR_Ext_bEspVehVld: data-element=R_Ext_bEspVehVld.Ext_bEspVehVld
        data send point DS_Tra_bGearManVld: data-element=P_Tra_bGearManVld.Tra_bGearManVld
        sync call SC_FRM_bDft_spdVeh: operation=R_FRM_bDft_spdVeh.GetFunctionPermission
      RE_TqSys_Sdl10ms_Tra: read-variable=[TqDem_tqTqRealSyncFuseMv_irv, TqDem_spdVehFil1_irv, TqDem_stGearratOverNRise_irv, TqDem_spdWhlFil1_irv, TqDem_n6CylEngMvFil_irv], written-variable=[Tra_spdVehGearRatCord_irv, TqDem_rPedPrssGrd_irv, TqDem_bGearRatCdnVld1_irv]
        10 x data receive point:
          DR_CoVSCtl_tqEfcReq: data-element=R_CoVSCtl_tqEfcReq.CoVSCtl_tqEfcReq
          dr_Ext_nEng: data-element=R_Ext_nEng.Ext_nEng
          dr_Ext_spdVeh: data-element=R_Ext_spdVeh.Ext_spdVeh
          dr_AccP_rAccP: data-element=R_AccP_rAccP.AccP_rAccP
          DR_Cha_bABSReg: data-element=R_Cha_bABSReg.Cha_bABSReg
          DR_TqSys_bClrCrossAcce: data-element=R_TqSys_bClrCrossAcce.TqSys_bClrCrossAcce
          dr_TqSys_nTarIdl: data-element=R_TqSys_nTarIdl.TqSys_nTarIdl
          dr_CoPt_noGearCord: data-element=R_CoPt_noGearCord.CoPt_noGearCord
          DR_Ext_nAvrFrntWhlCAN: data-element=R_Ext_nAvrFrntWhlCAN.Ext_nAvrFrntWhlCAN
          DR_Ext_noCylEng: data-element=R_Ext_noCylEng.Ext_noCylEng
        data send point DS_Tra_noGearMan: data-element=P_Tra_noGearMan.Tra_noGearMan
        data send point DS_TqDem_rGearRatAftRng: data-element=P_TqDem_rGearRatAftRng.TqDem_rGearRatAftRng
        sync call SC_FRM_bDft_CluPedPrss: operation=R_FRM_bDft_CluPedPrss.GetFunctionPermission
        sync call SC_FRM_bDft_bBrkPedPrss: operation=R_FRM_bDft_bBrkPedPrss.GetFunctionPermission
  swc implementation Imp_CoGBx: programming-language=C, behavior=IB_CoGBx
    code-descriptors:
      code CodeDescriptor: type=SRC
        37 x xfile:
          CoGBx2096_fct_c: url=CoGBx2096_fct.c
          TqSys_Sdl10ms_Tra_1_fct_c: url=TqSys_Sdl10ms_Tra_1_fct.c
          TqSys_Sdl10ms_CluPCord_fct_h: url=TqSys_Sdl10ms_CluPCord_fct.h
          TqSys_EveSync_Tra_2_fct_h: url=TqSys_EveSync_Tra_2_fct.h
          CoGBx_h: url=CoGBx.h
          CoGBx_2096_lut_c: url=CoGBx_2096_lut.c
          TqSys_EveSync_Tra_2_fct_c: url=TqSys_EveSync_Tra_2_fct.c
          TqSys_EveSync_Tra_1_fct_c: url=TqSys_EveSync_Tra_1_fct.c
          TqSys_Sdl10ms_Tra_2_fct_h: url=TqSys_Sdl10ms_Tra_2_fct.h
          TqSys_EveSync_Tra_1_fct_h: url=TqSys_EveSync_Tra_1_fct.h
          CoGbx_2040_calibrations_h: url=CoGbx_2040_calibrations.h
          TqSys_Sdl10ms_CoPtGearCord_fct_c: url=TqSys_Sdl10ms_CoPtGearCord_fct.c
          CoGBx_2096_lut_h: url=CoGBx_2096_lut.h
          CoGbx_2040_calibrations_c: url=CoGbx_2040_calibrations.c
          CoGBx_2096_calibrations_c: url=CoGBx_2096_calibrations.c
          TqSys_EveSyncFrame38D_Tra_fct_h: url=TqSys_EveSyncFrame38D_Tra_fct.h
          CoGBx_MemMap_h: url=CoGBx_MemMap.h
          TqSys_Sdl20ms_Tra_fct_c: url=TqSys_Sdl20ms_Tra_fct.c
          TqSys_Sdl10ms_Tra_3_fct_c: url=TqSys_Sdl10ms_Tra_3_fct.c
          CoGBx2096_fct_h: url=CoGBx2096_fct.h
          F0_Coordination_rapport_BV_lut_c: url=F0_Coordination_rapport_BV_lut.c
          TqSys_EveSyncFrame38D_Tra_fct_c: url=TqSys_EveSyncFrame38D_Tra_fct.c
          TqSys_Sdl10ms_Tra_3_fct_h: url=TqSys_Sdl10ms_Tra_3_fct.h
          TqSys_Sdl10ms_CoPtGearCord_fct_h: url=TqSys_Sdl10ms_CoPtGearCord_fct.h
          TqSys_Sdl10ms_Tra_2_fct_c: url=TqSys_Sdl10ms_Tra_2_fct.c
          CoGBx_c: url=CoGBx.c
          F0_Coordination_rapport_BV_lut_h: url=F0_Coordination_rapport_BV_lut.h
          TqSys_Sdl20ms_Tra_fct_h: url=TqSys_Sdl20ms_Tra_fct.h
          TqSys_Sdl10ms_Tra_1_fct_h: url=TqSys_Sdl10ms_Tra_1_fct.h
          TqSys_Sdl10ms_CluPCord_fct_c: url=TqSys_Sdl10ms_CluPCord_fct.c
          CoGbx_2097_calibrations_h: url=CoGbx_2097_calibrations.h
          TqSys_Sdl10ms_Tra_4_fct_h: url=TqSys_Sdl10ms_Tra_4_fct.h
          CoGBx_2096_calibrations_h: url=CoGBx_2096_calibrations.h
          TqSys_Sdl10ms_Tra_4_fct_c: url=TqSys_Sdl10ms_Tra_4_fct.c
          CoGbx_2097_calibrations_c: url=CoGbx_2097_calibrations.c
          TqSys_EveSyncFrame30D_Tra_fct_h: url=TqSys_EveSyncFrame30D_Tra_fct.h
          TqSys_EveSyncFrame30D_Tra_fct_c: url=TqSys_EveSyncFrame30D_Tra_fct.c
package /Components/SWC_CoGBx/CoGBx_IRVDatatypes
  boolean type DT_TqDem_bGearRatCdnVld1_irv: base-type=boolean
  boolean type DT_TqDem_stGearratOverNRise_irv: base-type=boolean
  6 x integer type:
    DT_TqDem_n6CylEngMvFil_irv: base-type=uint16, lower-limit=0, upper-limit=65535
    DT_TqDem_rPedPrssGrd_irv: base-type=int16, lower-limit=-32768, upper-limit=32767
    DT_TqDem_spdVehFil1_irv: base-type=uint16, lower-limit=0, upper-limit=65535
    DT_TqDem_spdWhlFil1_irv: base-type=uint16, lower-limit=0, upper-limit=65535
    DT_TqDem_tqTqRealSyncFuseMv_irv: base-type=int16, lower-limit=-32768, upper-limit=32767
    DT_Tra_spdVehGearRatCord_irv: base-type=uint32, lower-limit=0, upper-limit=4294967295
